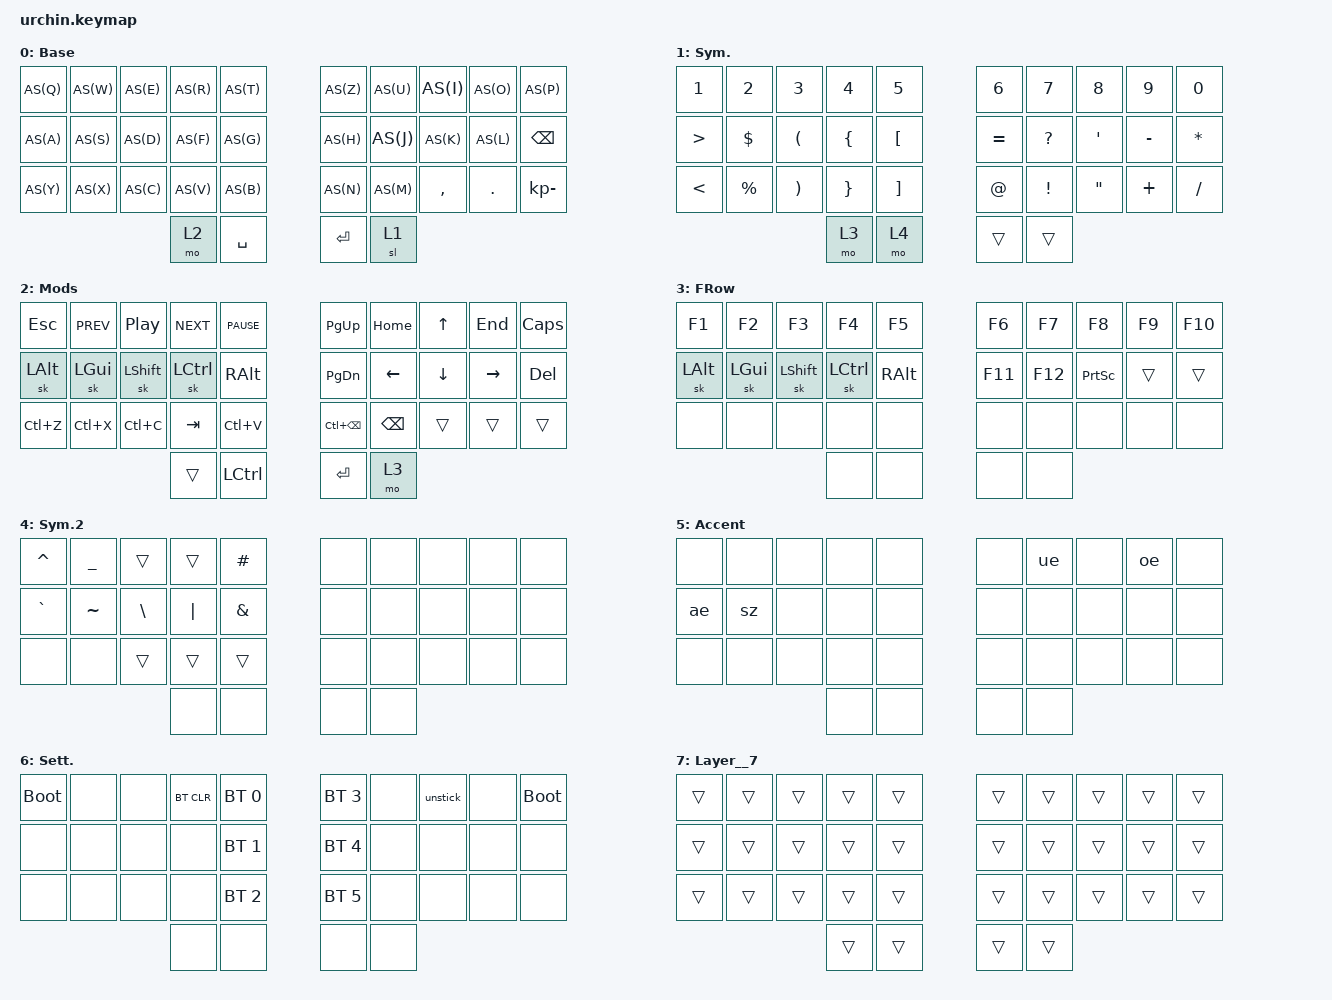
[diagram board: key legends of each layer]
/*
 * Copyright (c) 2020 duckyb
 *
 * SPDX-License-Identifier: MIT
 */

#include <behaviors.dtsi>
#include <dt-bindings/zmk/keys.h>
#include <dt-bindings/zmk/bt.h>

// Layer definitions

#define BASE 0
#define SYM 1
#define EXT 2
#define FNC 3
#define SYM2 4
#define ACCENT 5
#define SETTINGS 6

// -----------------

#define AS(keycode) &ht LS(keycode) keycode     // Autoshift Macro
#define AM(keycode) &am LG(keycode) keycode     // Autometa Macro


&sk {
    // don't release mods on other mods presses

    ignore-modifiers;
};

/ {
    behaviors {
        // Enables holding the first mod-tap key
        // by performing a tap-release-hold sequence.
        // To use it: "&qt KEYCODE1 KEYCODE2"

        qt: quick_tap {
            compatible = "zmk,behavior-hold-tap";
            label = "QUICK_TAP";
            #binding-cells = <2>;
            flavor = "hold-preferred";
            tapping-term-ms = <200>;
            quick-tap-ms = <200>;
            bindings =
                <&kp>,
                <&kp>;
        };

        ht: hold_tap {
            compatible = "zmk,behavior-hold-tap";
            label = "AUTO_SHIFT";
            #binding-cells = <2>;
            tapping_term_ms = <250>;
            quick_tap_ms = <0>;
            flavor = "tap-preferred";
            bindings = <&kp>, <&kp>;
        };

		am: auto_meta {
		compatible = "zmk,behavior-hold-tap";
		label = "AUTO_META";
		#binding-cells = <2>;
		tapping_term_ms = <250>;
		quick_tap_ms = <0>;
		flavor = "tap-preferred";
		bindings = <&kp>, <&kp>;
		};
    };

    macros {
        // sometimes my device thinks a modifier is being held down
        // pressing all modifiers fixes it.

        unstick: unstick {
            label = "ZM_unstick";
            compatible = "zmk,behavior-macro";
            #binding-cells = <0>;
            bindings = <&kp LSHIFT &kp RSHIFT &kp LCTRL &kp RCTRL &kp LALT &kp RALT &kp LGUI &kp RGUI>;
        };
        ae: ae {
            compatible = "zmk,behavior-macro";
            label = "ä";
            #binding-cells = <0>;
            bindings =
                <&macro_press>,
                <&kp LALT>,
                <&macro_tap>,
                <&kp N0 &kp N2 &kp N2 &kp N8>,
                <&macro_release>,
                <&kp LALT>;
        };
        oe: oe {
            compatible = "zmk,behavior-macro";
            label = "ö";
            #binding-cells = <0>;
            bindings =
                <&macro_press>,
                <&kp LALT>,
                <&macro_tap>,
                <&kp N0 &kp N2 &kp N4 &kp N6>,
                <&macro_release>,
                <&kp LALT>;
        };
        ue: ue {
            compatible = "zmk,behavior-macro";
            label = "ü";
            #binding-cells = <0>;
            bindings =
                <&macro_press>,
                <&kp LALT>,
                <&macro_tap>,
                <&kp N0 &kp N2 &kp N5 &kp N2>,
                <&macro_release>,
                <&kp LALT>;
        };
        sz: sz {
            compatible = "zmk,behavior-macro";
            label = "ß";
            #binding-cells = <0>;
            bindings =
                <&macro_press>,
                <&kp LALT>,
                <&macro_tap>,
                <&kp N0 &kp N2 &kp N2 &kp N3>,
                <&macro_release>,
                <&kp LALT>;
        };
    };

    combos {
        compatible = "zmk,combos";

        // both right thumb keys

        combo_accent {
            timeout-ms = <200>;
            key-positions = <32 33>;
            bindings = <&mo 5>;
        };

        // internal-left & external-right thumb keys

        combo_sym2 {
            timeout-ms = <200>;
            key-positions = <31 33>;
            bindings = <&mo 4>;
        };

        // both left thumb keys

        combo_settings {
            timeout-ms = <200>;
            key-positions = <30 31>;
            bindings = <&mo 6>;
        };

        // left index & middle fingers (home-row)
        // hold control & space for Adobe workflow

        combo_ctrl_space {
            timeout-ms = <200>;
            key-positions = <12 13>;
            bindings = <&kp LC(SPACE)>;
            layers = <BASE>;
        };
    };

    keymap {
        compatible = "zmk,keymap";

        // Base alpha layer

        default_layer {
            label = "Base";
            bindings = <
    AS(Q)    AS(W)    AS(E)    AS(R)    AS(T)           AS(Z)    AS(U)        AS(I)      AS(O)     AS(P)
    AS(A)    AS(S)    AS(D)    AS(F)    AS(G)           AS(H)    AS(J)        AS(K)      AS(L)     &kp BSPC
    AS(Y)    AS(X)    AS(C)    AS(V)    AS(B)           AS(N)    AS(M)        &kp COMMA  &kp DOT   &kp KP_MINUS
                           &mo 2    &kp SPACE          &kp ENTER    &sl 1
            >;
        };

        // Numbers and high frequency symbolsf

        sym_layer {
            label = "Sym.";
            bindings = <
&kp N1     &kp N2      &kp N3      &kp N4      &kp N5       &kp N6          &kp N7       &kp N8       &kp N9          &kp N0
&kp GT     &kp DOLLAR  &kp LPAR    &kp LBRC    &kp LBKT    &kp EQUAL    &kp QUESTION      &kp SQT    &kp MINUS    &kp ASTERISK
&kp LT     &kp PERCENT &kp RPAR    &kp RBRC    &kp RBKT       &kp AT        &kp EXCL    &kp DQT     &kp PLUS        &kp FSLH
                                        &mo 3       &mo 4    &trans          &trans
            >;
        };

        // Main modifiers and arrow keys

        ext_layer {
            label = "Mods";
            bindings = <
  &kp ESC    &kp C_PREV      &kp C_PP    &kp C_NEXT    &kp C_PAUSE       &kp PG_UP    &kp HOME      &kp UP      &kp END    &kp CAPS
 &sk LALT      &sk LGUI    &sk LSHIFT     &sk LCTRL       &kp RALT       &kp PG_DN    &kp LEFT    &kp DOWN    &kp RIGHT     &kp DEL
&kp LC(Z)     &kp LC(X)     &kp LC(C)       &kp TAB      &kp LC(V)    &kp LC(BSPC)    &kp BSPC      &trans       &trans      &trans
                                             &trans      &kp LCTRL       &kp ENTER       &mo 3
            >;
        };

        // Function keys with modifiers

        fnc_layer {
            label = "FRow";
            bindings = <
  &kp F1      &kp F2        &kp F3       &kp F4      &kp F5     &kp F6     &kp F7             &kp F8    &kp F9    &kp F10
&sk LALT    &sk LGUI    &sk LSHIFT    &sk LCTRL    &kp RALT    &kp F11    &kp F12             &kp PSCRN    &trans     &trans
   &none       &none         &none        &none       &none      &none      &none             &none     &none      &none
                                          &none       &none      &none      &none
            >;
        };

        // Low frequency symbols.

        symbols_2_layer {
            label = "Sym.2";
            bindings = <
&kp CARET    &kp UNDER      &trans      &trans    &kp HASH    &none    &none    &none    &none    &none
&kp GRAVE    &kp TILDE    &kp BSLH    &kp PIPE    &kp AMPS    &none    &none    &none    &none    &none
    &none        &none      &trans      &trans      &trans    &none    &none    &none    &none    &none
                                         &none       &none    &none    &none
            >;
        };

        // Used to type regional accents.

        accent_layer {
            label = "Accent";
            bindings = <
&none    &none    &none    &none    &none    &none      &ue    &none      &oe    &none
  &ae      &sz    &none    &none    &none    &none    &none    &none    &none    &none
&none    &none    &none    &none    &none    &none    &none    &none    &none    &none
                           &none    &none    &none    &none
            >;
        };

        // Used to change the keyboard's settings.

        settings_layer {
            label = "Sett.";
            bindings = <
&bootloader    &none    &none    &bt BT_CLR    &bt BT_SEL 0    &bt BT_SEL 3    &none    &unstick    &none    &bootloader
      &none    &none    &none         &none    &bt BT_SEL 1    &bt BT_SEL 4    &none       &none    &none          &none
      &none    &none    &none         &none    &bt BT_SEL 2    &bt BT_SEL 5    &none       &none    &none          &none
                                      &none           &none           &none    &none
            >;
        };

        Layer__7 {
            bindings = <
&trans    &trans    &trans    &trans    &trans    &trans    &trans    &trans    &trans    &trans
&trans    &trans    &trans    &trans    &trans    &trans    &trans    &trans    &trans    &trans
&trans    &trans    &trans    &trans    &trans    &trans    &trans    &trans    &trans    &trans
                              &trans    &trans    &trans    &trans
            >;
        };
    };
};
